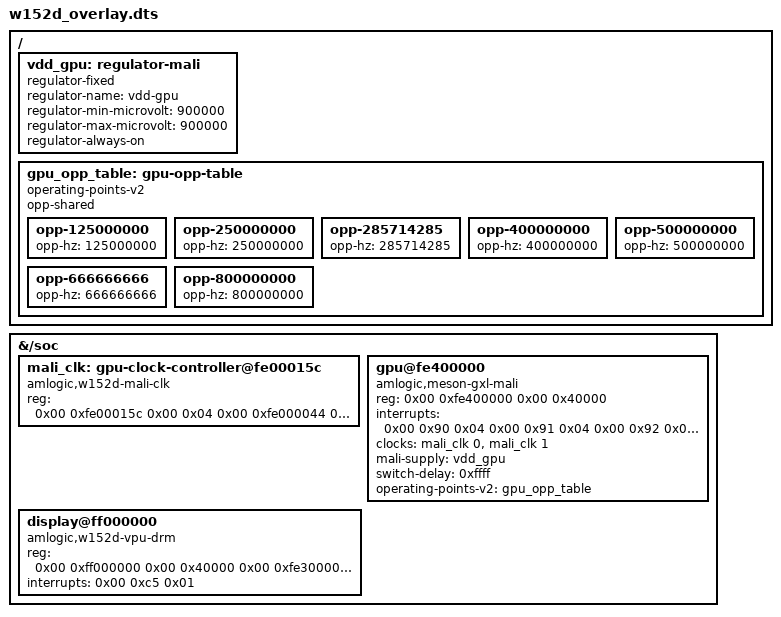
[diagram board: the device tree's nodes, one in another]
/dts-v1/;
/plugin/;

/ {
	fragment@0 {
		target-path = "/";
		__overlay__ {
			vdd_gpu: regulator-mali {
				compatible = "regulator-fixed";
				regulator-name = "vdd-gpu";
				regulator-min-microvolt = <900000>;
				regulator-max-microvolt = <900000>;
				regulator-always-on;
			};

			gpu_opp_table: gpu-opp-table {
				compatible = "operating-points-v2";
				opp-shared;

				opp-125000000 {
					opp-hz = /bits/ 64 <125000000>;
				};

				opp-250000000 {
					opp-hz = /bits/ 64 <250000000>;
				};

				opp-285714285 {
					opp-hz = /bits/ 64 <285714285>;
				};

				opp-400000000 {
					opp-hz = /bits/ 64 <400000000>;
				};

				opp-500000000 {
					opp-hz = /bits/ 64 <500000000>;
				};

				opp-666666666 {
					opp-hz = /bits/ 64 <666666666>;
				};

				opp-800000000 {
					opp-hz = /bits/ 64 <800000000>;
				};
			};
		};
	};

	fragment@1 {
		target-path = "/soc";
		__overlay__ {
			#address-cells = <2>;
			#size-cells = <2>;

			mali_clk: gpu-clock-controller@fe00015c {
				compatible = "amlogic,w152d-mali-clk";
				reg = <0x00 0xfe00015c 0x00 0x04
				       0x00 0xfe000044 0x00 0x04
				       0x00 0xfe00004c 0x00 0x04>;
				#clock-cells = <1>;
			};

			gpu@fe400000 {
				compatible = "amlogic,meson-gxl-mali", "arm,mali-450";
				reg = <0x00 0xfe400000 0x00 0x40000>;
				interrupts = <0x00 0x90 0x04
				              0x00 0x91 0x04
				              0x00 0x92 0x04
				              0x00 0x93 0x04
				              0x00 0x94 0x04
				              0x00 0x95 0x04
				              0x00 0x96 0x04
				              0x00 0x97 0x04>;
				interrupt-names = "gp", "gpmmu", "pp", "pmu", "pp0", "ppmmu0", "pp1", "ppmmu1";
				clocks = <&mali_clk 0>, <&mali_clk 1>;
				clock-names = "bus", "core";
				mali-supply = <&vdd_gpu>;
				switch-delay = <0xffff>;
				operating-points-v2 = <&gpu_opp_table>;
			};

			display@ff000000 {
				compatible = "amlogic,w152d-vpu-drm";
				reg = <0x00 0xff000000 0x00 0x40000
				       0x00 0xfe300000 0x00 0x10000
				       0x00 0xfe004140 0x00 0x10>;
				reg-names = "vpu", "hdmitx_top", "gpioh_in";
				interrupts = <0x00 0xc5 0x01>;
				interrupt-names = "viu-vsync";
			};
		};
	};
};
